# H616 register map
Vendor: Allwinner; Series: H616; File version: 0.1
CPU: other 0, little endian, MPU, no FPU, 0 interrupt priority bits
Registers are 32-bit, read-write, reset 0x0 unless marked. A register's access mark holds for its fields unless they carry their own. Offsets are from the block's base; lines under a group give offsets from that group; [hi:lo] are bit positions; {n}, {i} and the like mark numbered series; 'fields as' and 'values as' point back to an identical list; <NAME> marks a mode.

## Memory map
0x01904000 CE_NS
0x01904800 CE_S
0x03000000 SYS_CFG
0x03001000 CCU
0x03002000 DMA
0x03005000 High_Speed_Timer
0x03009000 Timer
0x0300A000 PWM
0x030F0000 IOMMU
0x04011000 NDFC
0x04020000 SMHC0
0x04021000 SMHC1
0x04022000 SMHC2
0x05000000 UART0
0x05000400 UART1
0x05000800 UART2
0x05000C00 UART3
0x05001000 UART4
0x05001400 UART5
0x05002000 TWI0
0x05002400 TWI1
0x05002800 TWI2
0x05002C00 TWI3
0x05003000 TWI4
0x05010000 SPI0
0x05011000 SPI1
0x05020000 EMAC0
0x05030000 EMAC1
0x05060000 TSC
0x05060040 TSG
0x05060100 TSF
0x05060180 TSD
0x05070400 Thermal_Sensor
0x05070800 LRADC
0x05093000 OWA
0x05095000 DMIC
0x05096000 Audio_Codec
0x05097000 AHUB
0x05200000 USB1
0x05310000 USB2
0x05311000 USB3
0x06515000 TCON_TV0
0x06516000 TCON_TV1
0x06520000 TVE_TOP
0x06524000 TVE
0x07000000 RTC
0x07022000 GPIO(PL)
0x07040000 CIR_RX
0x07081400 R-TWI0
0x08100000 CPU_SUBSYS_CTRL
0x09010000 C0_CPUX_CFG

## CPU_SUBSYS_CTRL
Base 0x08100000
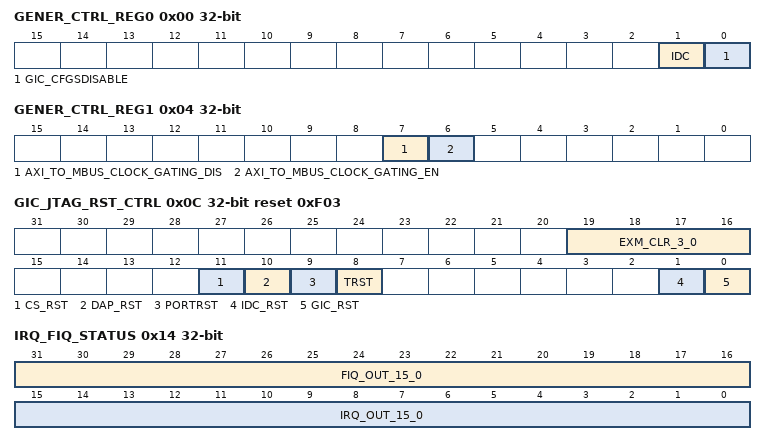
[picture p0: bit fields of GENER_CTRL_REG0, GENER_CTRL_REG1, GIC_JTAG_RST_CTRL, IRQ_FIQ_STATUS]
0x00 GENER_CTRL_REG0 — General Control Register0
  [1] IDC — clock enable 0: disable IDC clock 1: enable IDC clock
    0=disable IDC clock; 1=enable IDC clock
  [0] GIC_CFGSDISABLE — Disables write access to some secure GIC registers.
0x04 GENER_CTRL_REG1 — General Control Register1
  [7] AXI_TO_MBUS_CLOCK_GATING_DIS — to MBUS Clock Gating disable, the priority of this bit is higher than bit[6]
  [6] AXI_TO_MBUS_CLOCK_GATING_EN — to MBUS Clock Gating enable
0x0C GIC_JTAG_RST_CTRL reset 0xF03 — GIC and Jtag Reset Control Register
  [19:16] EXM_CLR_3_0 — EXM_CLR[3:0] Clear the status of interface, for debug
  [11] CS_RST — CoreSight Reset 0: assert 1: de-assert
    0=assert; 1=deassert
  [10] DAP_RST — DAP Reset 0: assert 1: de-assert
    0=assert; 1=deassert
  [9] PORTRST — Jtag portrst 0: assert 1: de-assert
    0=assert; 1=deassert
  [8] TRST — Jtag trst 0: assert 1: de-assert
    0=assert; 1=deassert
  [1] IDC_RST — Interrupt delay controller reset 0: assert 1: de-assert
    0=assert; 1=deassert
  [0] GIC_RST — GIC_reset_cpu_reg 0: assert 1: de-assert
    0=assert; 1=deassert
0x10 C0_INT_EN reset 0xFFFF — Cluster0 Interrupt Enable Control Register
  [15:0] C0_GIC_EN — Interrupt enable control register. Mask irq_out/firq_out to system domain.
0x14 IRQ_FIQ_STATUS
  [31:16] FIQ_OUT_15_0, [15:0] IRQ_OUT_15_0
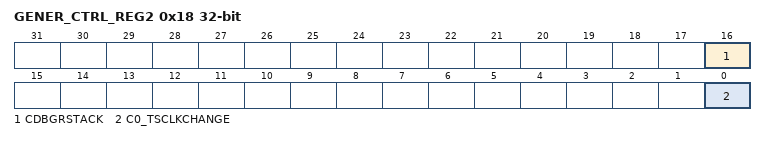
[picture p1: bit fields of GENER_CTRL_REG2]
0x18 GENER_CTRL_REG2 — General Control Register2
  [16] CDBGRSTACK — Debug Reset ACK
  [0] C0_TSCLKCHANGE — Cluster 0 Time Stamp change bit
0x1C DBG_STATE — Debug State Register
  [0] C0_DBG_STATE ro — Cluster 0 is in debug mode or normal mode

## CE_NS
Base 0x01904000
Same registers: CE_S 0x01904800
0x00 CE_TDA — Task Descriptor Address
  [31:0] TASK — Task Descriptor Address Must be word address.
0x08 CE_ICR — Interrupt Control Register
  [3:0] TASK — Task Channel3~0 Interrupt Enable 0: Disable 1: Enable
0x0C CE_ISR — Interrupt Status Register
  [3:0] TASK write-1-clears — Task Channel3~0 End Pending 0: Not finished 1: Finished It indicates if task has been completed . Write `1` to clear it.
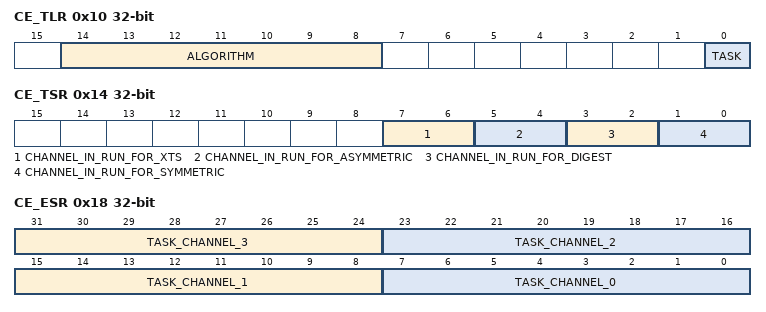
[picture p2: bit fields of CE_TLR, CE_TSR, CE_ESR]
0x10 CE_TLR — Task Load Register
  [14:8] ALGORITHM — Algorithm type, the same with type field in description common control.
  [0] TASK — Task Load When setting, CE can load the descriptor of task if task FIFO is not full.
0x14 CE_TSR — Task Status Register
  [all] fields
    {v}=task_channel{v} (v=0..3)
  [7:6] CHANNEL_IN_RUN_FOR_XTS ro — indicate which channel in run for XTS 00: task channel0 01: task channel1 10: task channel2 11: task channel3
  [5:4] CHANNEL_IN_RUN_FOR_ASYMMETRIC ro — indicate which channel in run for asymmetric 00: task channel0 01: task channel1 10: task channel2 11: task channel3
  [3:2] CHANNEL_IN_RUN_FOR_DIGEST ro — indicate which channel in run for digest 00: task channel0 01: task channel1 10: task channel2 11: task channel3
  [1:0] CHANNEL_IN_RUN_FOR_SYMMETRIC ro — indicate which channel in run for symmetric 00: task channel0 01: task channel1 10: task channel2 11: task channel3
0x18 CE_ESR — Error Status Register
  [31:24] TASK_CHANNEL_3 write-1-clears — Task channel 3 error type. (the same for other channels) Bit 24: algorithm not support Bit 25: data length error Bit 26: keysram access error. Write `1` to clear. Bit 29: address invalid other: reserved
  [23:16] TASK_CHANNEL_2 write-1-clears — Task channel 2 error type. Bit 16: algorithm not support Bit 17: data length error Bit 18: keysram access error. Write `1` to clear. Bit 21: address invalid other: reserved
  [15:8] TASK_CHANNEL_1 write-1-clears — Task channel 1 error type. Bit 8: algorithm not support Bit 9: data length error Bit 10: keysram access error. Write `1` to clear. Bit 13: address invalid other: reserved
  [7:0] TASK_CHANNEL_0 write-1-clears — Task channel 0 error type. Bit 0: algorithm not support Bit 1: data length error Bit 2: keysram access error. Write `1` to clear. Bit 5: address invalid other: reserved
0x24 CE_SCSA — Symmetric Algorithm DMA Current Source Address
  [31:0] SYMMETRIC ro — Symmetric algorithm current source address read by DMA.
0x28 CE_SCDA — Symmetric Algorithm DMA Current Destination Address
  [31:0] SYMMETRIC ro — Symmetric algorithm current destination address written by DMA.
0x34 CE_HCSA — HASH Algorithm DMA Current Source Address
  [31:0] HASH ro — algorithm current source address read by DMA.
0x38 CE_HCDA — HASH Algorithm DMA Current Destination Address
  [31:0] HASH ro — algorithm current destination address written by DMA.
0x44 CE_ACSA — Asymmetric Algorithm DMA Current Source Address
  [31:0] ASYMMETRIC ro — Asymmetric algorithm current source address read by DMA.
0x48 CE_ACDA — Asymmetric Algorithm DMA Current Destination Address
  [31:0] ASYMMETRIC ro — Asymmetric algorithm current destination address written by DMA.
0x54 CE_XCSA — XTS Algorithm DMA Current Source Address
  [31:0] XTS ro — algorithm current source address read by DMA.
0x58 CE_XCDA — XTS Algorithm DMA Current Destination Address
  [31:0] XTS ro — algorithm current destination address written by DMA.

## Licence text in the file
questionable
